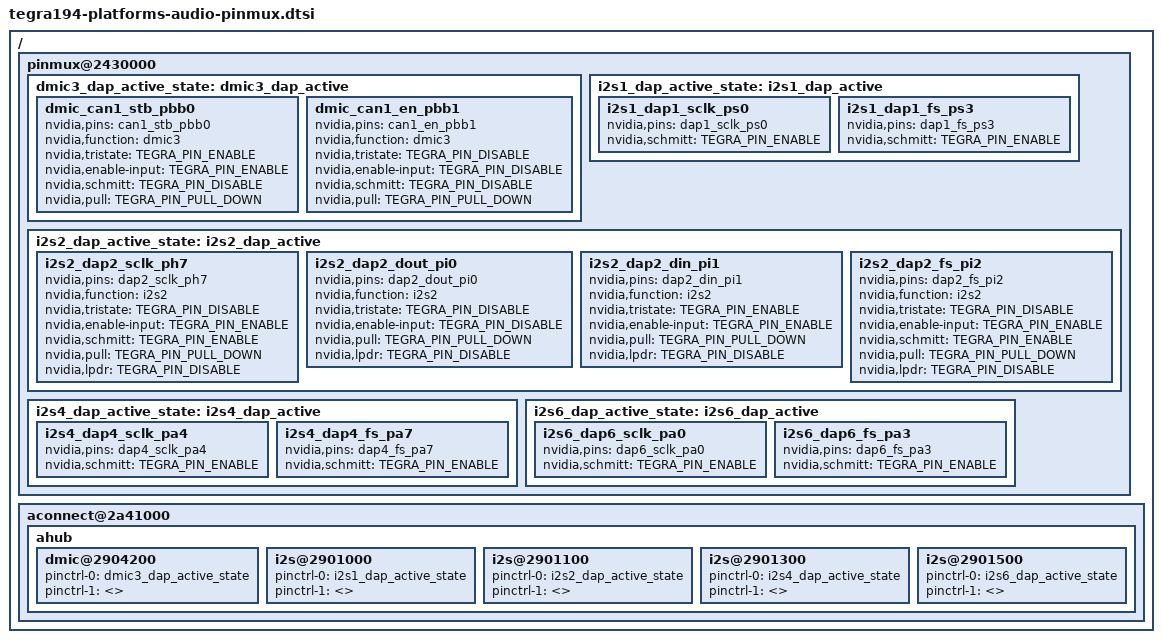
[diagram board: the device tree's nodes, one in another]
/*
 * Pinmux controls for Audio
 *
 * Copyright (c) 2017 - 2018, NVIDIA CORPORATION.  All rights reserved.
 *
 * This program is free software; you can redistribute it and/or modify
 * it under the terms of the GNU General Public License as published by
 * the Free Software Foundation; version 2 of the License.
 *
 * This program is distributed in the hope that it will be useful, but WITHOUT
 * ANY WARRANTY; without even the implied warranty of MERCHANTABILITY or
 * FITNESS FOR A PARTICULAR PURPOSE.  See the GNU General Public License for
 * more details.
 */

/ {
	pinmux@2430000 {
		/* Dynamic pinmux config for DMIC3 */
		dmic3_dap_active_state: dmic3_dap_active {
			dmic_can1_stb_pbb0 {
				nvidia,pins = "can1_stb_pbb0";
				nvidia,function = "dmic3";
				nvidia,tristate = <TEGRA_PIN_ENABLE>;
				nvidia,enable-input = <TEGRA_PIN_ENABLE>;
				nvidia,schmitt = <TEGRA_PIN_DISABLE>;
				nvidia,pull = <TEGRA_PIN_PULL_DOWN>;
			};
			dmic_can1_en_pbb1 {
				nvidia,pins = "can1_en_pbb1";
				nvidia,function = "dmic3";
				nvidia,tristate = <TEGRA_PIN_DISABLE>;
				nvidia,enable-input = <TEGRA_PIN_DISABLE>;
				nvidia,schmitt = <TEGRA_PIN_DISABLE>;
				nvidia,pull = <TEGRA_PIN_PULL_DOWN>;
			};
		};

		i2s1_dap_active_state: i2s1_dap_active {
			i2s1_dap1_sclk_ps0 {
				nvidia,pins = "dap1_sclk_ps0";
				nvidia,schmitt = <TEGRA_PIN_ENABLE>;
			};
			i2s1_dap1_fs_ps3 {
				nvidia,pins = "dap1_fs_ps3";
				nvidia,schmitt = <TEGRA_PIN_ENABLE>;
			};
		};

		/* Dynamic pinmux config for I2S2 */
		i2s2_dap_active_state: i2s2_dap_active {
			i2s2_dap2_sclk_ph7 {
				nvidia,pins = "dap2_sclk_ph7";
				nvidia,function = "i2s2";
				nvidia,tristate = <TEGRA_PIN_DISABLE>;
				nvidia,enable-input = <TEGRA_PIN_ENABLE>;
				nvidia,schmitt = <TEGRA_PIN_ENABLE>;
				nvidia,pull = <TEGRA_PIN_PULL_DOWN>;
				nvidia,lpdr = <TEGRA_PIN_DISABLE>;
			};
			i2s2_dap2_dout_pi0 {
				nvidia,pins = "dap2_dout_pi0";
				nvidia,function = "i2s2";
				nvidia,tristate = <TEGRA_PIN_DISABLE>;
				nvidia,enable-input = <TEGRA_PIN_DISABLE>;
				nvidia,pull = <TEGRA_PIN_PULL_DOWN>;
				nvidia,lpdr = <TEGRA_PIN_DISABLE>;
			};
			i2s2_dap2_din_pi1 {
				nvidia,pins = "dap2_din_pi1";
				nvidia,function = "i2s2";
				nvidia,tristate = <TEGRA_PIN_ENABLE>;
				nvidia,enable-input = <TEGRA_PIN_ENABLE>;
				nvidia,pull = <TEGRA_PIN_PULL_DOWN>;
				nvidia,lpdr = <TEGRA_PIN_DISABLE>;
			};
			i2s2_dap2_fs_pi2 {
				nvidia,pins = "dap2_fs_pi2";
				nvidia,function = "i2s2";
				nvidia,tristate = <TEGRA_PIN_DISABLE>;
				nvidia,enable-input = <TEGRA_PIN_ENABLE>;
				nvidia,schmitt = <TEGRA_PIN_ENABLE>;
				nvidia,pull = <TEGRA_PIN_PULL_DOWN>;
				nvidia,lpdr = <TEGRA_PIN_DISABLE>;
			};
		};

		/* Dynamic pinmux config for I2S4 */
		i2s4_dap_active_state: i2s4_dap_active {
			i2s4_dap4_sclk_pa4 {
				nvidia,pins = "dap4_sclk_pa4";
				nvidia,schmitt = <TEGRA_PIN_ENABLE>;
			};
			i2s4_dap4_fs_pa7 {
				nvidia,pins = "dap4_fs_pa7";
				nvidia,schmitt = <TEGRA_PIN_ENABLE>;
			};
		};

		/* Dynamic pinmux config for I2S6 */
		i2s6_dap_active_state: i2s6_dap_active {
			i2s6_dap6_sclk_pa0 {
				nvidia,pins = "dap6_sclk_pa0";
				nvidia,schmitt = <TEGRA_PIN_ENABLE>;
			};
			i2s6_dap6_fs_pa3 {
				nvidia,pins = "dap6_fs_pa3";
				nvidia,schmitt = <TEGRA_PIN_ENABLE>;
			};
		};
	};

	/* dynamic pinmux overrides */
	aconnect@2a41000 {
		ahub {
			dmic@2904200 {
				pinctrl-names = "dap_active", "dap_inactive";
				pinctrl-0 = <&dmic3_dap_active_state>;
				pinctrl-1 = <>;
			};
			i2s@2901000 {
				pinctrl-names = "dap_active", "dap_inactive";
				pinctrl-0 = <&i2s1_dap_active_state>;
				pinctrl-1 = <>;
			};
			i2s@2901100 {
				pinctrl-names = "dap_active", "dap_inactive";
				pinctrl-0 = <&i2s2_dap_active_state>;
				pinctrl-1 = <>;
			};
			i2s@2901300 {
				pinctrl-names = "dap_active", "dap_inactive";
				pinctrl-0 = <&i2s4_dap_active_state>;
				pinctrl-1 = <>;
			};
			i2s@2901500 {
				pinctrl-names = "dap_active", "dap_inactive";
				pinctrl-0 = <&i2s6_dap_active_state>;
				pinctrl-1 = <>;
			};
		};
	};
};
